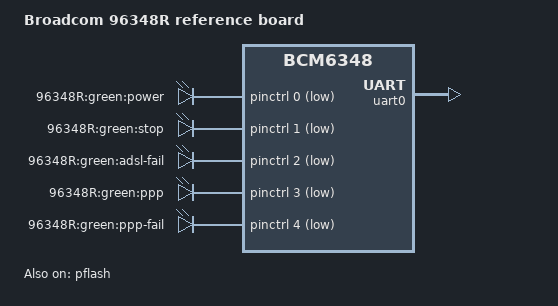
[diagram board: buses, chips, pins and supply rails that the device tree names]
/dts-v1/;

#include "bcm6348.dtsi"

#include <dt-bindings/input/input.h>

/ {
	model = "Broadcom 96348R reference board";
	compatible = "brcm,bcm96348r", "brcm,bcm6348";

	chosen {
		bootargs = "rootfstype=squashfs,jffs2 noinitrd console=ttyS0,115200";
		stdout-path = "serial0:115200n8";
	};

	gpio-leds {
		compatible = "gpio-leds";

		power_green {
			label = "96348R:green:power";
			gpios = <&pinctrl 0 1>;
			default-state = "on";
		};
		stop_green {
			label = "96348R:green:stop";
			gpios = <&pinctrl 1 1>;
		};
		adsl_fail_green {
			label = "96348R:green:adsl-fail";
			gpios = <&pinctrl 2 1>;
		};
		ppp_green {
			label = "96348R:green:ppp";
			gpios = <&pinctrl 3 1>;
		};
		ppp_fail_green {
			label = "96348R:green:ppp-fail";
			gpios = <&pinctrl 4 1>;
		};
	};
};

&pflash {
	status = "ok";

	linux,part-probe = "bcm63xxpart";

	partitions {
		compatible = "brcm,bcm963xx-cfe-nor-partitions";
	};
};

&pinctrl {
	pinctrl-names = "default";
	pinctrl-0 = <&pinctrl_pci>;
};

&uart0 {
	status = "ok";
};
